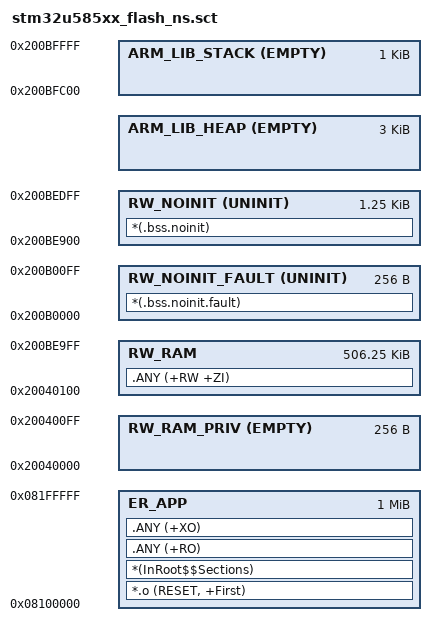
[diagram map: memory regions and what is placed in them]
#! armclang -E --target=arm-arm-none-eabi -mcpu=cortex-m33 -xc
/* command above MUST be in first line (no comment above!) */

/******************************************************************************
 * @file     stm32u585xx_flash_ns.sct
 * @brief    GNU Linker Script for STM32U575xx Device
 * @version  V2.0.0
 * @date     10. March 2023
 ******************************************************************************/
/*
 * Copyright (c) 2023 Arm Limited. All rights reserved.
 *
 * SPDX-License-Identifier: Apache-2.0
 *
 * Licensed under the Apache License, Version 2.0 (the License); you may
 * not use this file except in compliance with the License.
 * You may obtain a copy of the License at
 *
 * www.apache.org/licenses/LICENSE-2.0
 *
 * Unless required by applicable law or agreed to in writing, software
 * distributed under the License is distributed on an AS IS BASIS, WITHOUT
 * WARRANTIES OR CONDITIONS OF ANY KIND, either express or implied.
 * See the License for the specific language governing permissions and
 * limitations under the License.
 */

/*
// <<< Use Configuration Wizard in Context Menu >>>
 */

/*
// <h> Flash Configuration
//   <i> specify the base address and the size of the used Flash
//   <o0> Flash Base Address <0x0-0xFFFFFFFF:8>
//   <o1> Flash Size (in Bytes) <0x0-0xFFFFFFFF:8>
// </h>
 */
#define __ROM_BASE           0x08100000
#define __ROM_SIZE           0x00100000

/*
// <h> RAM Configuration
//   <i> specify the base address and the complete size of the used RAM
//   <o0> RAM Base Address    <0x0-0xFFFFFFFF:8>
//   <o1> RAM Size (in Bytes) <0x0-0xFFFFFFFF:8>
// </h>
 */
#define __RAM_BASE           0x20040000
#define __RAM_SIZE           0x00080000

/*
// <h> Stack / Heap Configuration
//   <i> specify the size used for the Stack, Heap sections
//   <o0> Stack Size (in Bytes) <0x0-0xFFFFFFFF:8>
//   <o1> Heap Size (in Bytes) <0x0-0xFFFFFFFF:8>
// </h>
 */
#define __STACK_SIZE         0x00000400
#define __HEAP_SIZE          0x00000C00

/*
// <h> NOINIT Data Configuration
//   <i> specify the size of the section which holds the uninitialized data
//   <o0>  NOINIT Size (in Bytes) <0x0-0xFFFFFFFF:32>
// </h>
 */
#define __NOINIT_SIZE        0x00000500

/*
// <<< end of configuration section >>>
 */


#define __STACK_TOP  ( __RAM_BASE + __RAM_SIZE )                     /* starts at end of RAM */
#define __HEAP_BASE  ( AlignExpr(+0, 8) )                            /* starts after RW_RAM or RW_NOINIT section, 8 byte aligned */

#define __LR_BASE          ( __ROM_BASE )
#define __LR_SIZE          ( __ROM_SIZE )

#define __RW_BASE          ( __RAM_BASE )
#define __RW_SIZE          ( __RAM_SIZE - __STACK_SIZE - __HEAP_SIZE - __NOINIT_SIZE - 0x200 )
#define __RW_NOINIT_BASE   ( __RAM_BASE + __RW_SIZE )                /* starts after RW_RAM section */


LR_APP __LR_BASE __LR_SIZE  {                                        /* load region for application */
  ER_APP __LR_BASE __LR_SIZE  {                                      /* execution region for application */
   *.o (RESET, +First)
   *(InRoot$$Sections)
   .ANY (+RO)
   .ANY (+XO)
  }

  RW_RAM_PRIV __RW_BASE EMPTY 0x100 {                                /* RAM allowing privileged access only (for showing MemManage fault) */
  }

  RW_RAM (__RW_BASE + 0x100) __RW_SIZE {                             /* RW, ZI data */
   .ANY (+RW +ZI)
  }

  RW_NOINIT_FAULT 0x200B0000 UNINIT 0x100 {                          /* Uninitialized memory for Fault information (ARM_FaultInfo) */
    *(.bss.noinit.fault)
  }

#if __NOINIT_SIZE > 0
  RW_NOINIT __RW_NOINIT_BASE UNINIT __NOINIT_SIZE {                  /* no init data */
    *(.bss.noinit)
  }
#endif

#if __HEAP_SIZE > 0
  ARM_LIB_HEAP  __HEAP_BASE EMPTY  __HEAP_SIZE  {                    /* empty region for heap */
  }
#endif

  ARM_LIB_STACK __STACK_TOP EMPTY -__STACK_SIZE {                    /* empty region for stack */
  }
}
